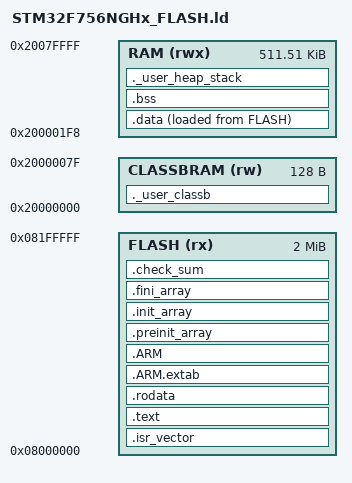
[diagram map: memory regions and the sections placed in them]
/*
*****************************************************************************
**

**  File        : STM32F756NGHx_FLASH.ld
**
**  Abstract    : Linker script for STM32F756NGHx Device with
**                1024KByte FLASH, 320KByte RAM
**
**                Set heap size, stack size and stack location according
**                to application requirements.
**
**                Set memory bank area and size if external memory is used.
**
**  Target      : STMicroelectronics STM32
**
**
**  Distribution: The file is distributed as is, without any warranty
**                of any kind.
**
*****************************************************************************
** @attention
**
** <h2><center>&copy; COPYRIGHT(c) 2014 Ac6</center></h2>
**
** Redistribution and use in source and binary forms, with or without modification,
** are permitted provided that the following conditions are met:
**   1. Redistributions of source code must retain the above copyright notice,
**      this list of conditions and the following disclaimer.
**   2. Redistributions in binary form must reproduce the above copyright notice,
**      this list of conditions and the following disclaimer in the documentation
**      and/or other materials provided with the distribution.
**   3. Neither the name of Ac6 nor the names of its contributors
**      may be used to endorse or promote products derived from this software
**      without specific prior written permission.
**
** THIS SOFTWARE IS PROVIDED BY THE COPYRIGHT HOLDERS AND CONTRIBUTORS "AS IS"
** AND ANY EXPRESS OR IMPLIED WARRANTIES, INCLUDING, BUT NOT LIMITED TO, THE
** IMPLIED WARRANTIES OF MERCHANTABILITY AND FITNESS FOR A PARTICULAR PURPOSE ARE
** DISCLAIMED. IN NO EVENT SHALL THE COPYRIGHT HOLDER OR CONTRIBUTORS BE LIABLE
** FOR ANY DIRECT, INDIRECT, INCIDENTAL, SPECIAL, EXEMPLARY, OR CONSEQUENTIAL
** DAMAGES (INCLUDING, BUT NOT LIMITED TO, PROCUREMENT OF SUBSTITUTE GOODS OR
** SERVICES; LOSS OF USE, DATA, OR PROFITS; OR BUSINESS INTERRUPTION) HOWEVER
** CAUSED AND ON ANY THEORY OF LIABILITY, WHETHER IN CONTRACT, STRICT LIABILITY,
** OR TORT (INCLUDING NEGLIGENCE OR OTHERWISE) ARISING IN ANY WAY OUT OF THE USE
** OF THIS SOFTWARE, EVEN IF ADVISED OF THE POSSIBILITY OF SUCH DAMAGE.
**
*****************************************************************************
*/

/* Entry Point */
ENTRY(Reset_Handler)

/* Highest address of the user mode stack */
_estack = 0x2004FFFF;    /* end of RAM */
/* Generate a link error if heap and stack don't fit into RAM */
_Min_Heap_Size = 0x200;      /* required amount of heap  */
_Min_Stack_Size = 0x400; /* required amount of stack */

/* Specify the memory areas */
MEMORY
{
FLASH (rx)      : ORIGIN = 0x08000000, LENGTH = 2048K
CLASSBRAM (rw)   : ORIGIN = 0x20000000, LENGTH = 0x80
/* RAM (xrw)        : ORIGIN = 0x20000080, LENGTH = 0x4FF80 */
 RAM (rwx)  : ORIGIN = 0x200001F8, LENGTH = 512K - 0x1F8
}

/* Define output sections */
SECTIONS
{
  /* The startup code goes first into FLASH */
  .isr_vector :
  {
    . = ALIGN(4);
    KEEP(*(.isr_vector)) /* Startup code */
    . = ALIGN(4);
  } >FLASH

  /* The program code and other data goes into FLASH */
  .text :
  {
    . = ALIGN(4);
    *(.text)           /* .text sections (code) */
    *(.text*)          /* .text* sections (code) */
    *(.glue_7)         /* glue arm to thumb code */
    *(.glue_7t)        /* glue thumb to arm code */
    *(.eh_frame)

    KEEP (*(.init))
    KEEP (*(.fini))

    . = ALIGN(4);
    _etext = .;        /* define a global symbols at end of code */
  } >FLASH

  /* Constant data goes into FLASH */
  .rodata :
  {
    . = ALIGN(4);
    *(.rodata)         /* .rodata sections (constants, strings, etc.) */
    *(.rodata*)        /* .rodata* sections (constants, strings, etc.) */
    . = ALIGN(4);
  } >FLASH

  .ARM.extab   : { *(.ARM.extab* .gnu.linkonce.armextab.*) } >FLASH
  .ARM : {
    __exidx_start = .;
    *(.ARM.exidx*)
    __exidx_end = .;
  } >FLASH

  .preinit_array     :
  {
    PROVIDE_HIDDEN (__preinit_array_start = .);
    KEEP (*(.preinit_array*))
    PROVIDE_HIDDEN (__preinit_array_end = .);
  } >FLASH
  
  .init_array :
  {
    PROVIDE_HIDDEN (__init_array_start = .);
    KEEP (*(SORT(.init_array.*)))
    KEEP (*(.init_array*))
    PROVIDE_HIDDEN (__init_array_end = .);
  } >FLASH
  
  .fini_array :
  {
    PROVIDE_HIDDEN (__fini_array_start = .);
    KEEP (*(SORT(.fini_array.*)))
    KEEP (*(.fini_array*))
    PROVIDE_HIDDEN (__fini_array_end = .);
  } >FLASH

  /* used by the startup to initialize data */
  _sidata = LOADADDR(.data);

  /* Initialized data sections goes into RAM, load LMA copy after code */
  .data : 
  {
    . = ALIGN(4);
    _sdata = .;        /* create a global symbol at data start */
    *(stm32fxx_STLstartup.o)
    *(.data)           /* .data sections */
    *(.data*)          /* .data* sections */

    . = ALIGN(4);
    _edata = .;        /* define a global symbol at data end */
  } >RAM AT> FLASH

  /* check sum specified by user at the end of program in flash */
  .check_sum :
  {
  	. = ALIGN(64); /* alignement must correspond to the size of tested block at FLASH run time test */
  	PROVIDE( _Check_Sum = . );
  	/* check sum defined by user - see user manual */
  	/* LONG(0xc60373f1); */
    	LONG(0x0067B29E);
  } >FLASH
  
  /* Uninitialized data section */
  . = ALIGN(4);
  .bss(NOLOAD) :
  {
    /* This is used by the startup in order to initialize the .bss secion */
    _sbss = .;         /* define a global symbol at bss start */
    __bss_start__ = _sbss;
    *(.bss)
    *(.bss*)
    *(COMMON)

    . = ALIGN(4);
    _ebss = .;         /* define a global symbol at bss end */
    __bss_end__ = _ebss;
  } >RAM

  /* User_heap_stack section, used to check that there is enough RAM left */
  /* Willy Add __end__ = .; because mbed need it */
  ._user_heap_stack(NOLOAD) :
  {
    . = ALIGN(8);
	__end__ = .;     
    PROVIDE ( end_ = . );
    PROVIDE ( _end = . );
    . = . + _Min_Heap_Size;
    *(.stack_bottom)
    *(.stack_bottom*)
    . = . + _Min_Stack_Size;
    . = ALIGN(8);
  } >RAM

  
  /* User class B RAM region */
  ._user_classb(NOLOAD) :
  {
    . = ALIGN(4);
    *(.run_time_ram_buf)
    *(.run_time_ram_buf*)
    *(.run_time_ram_pnt)
    *(.run_time_ram_pnt*)
    
    . = ALIGN(4);
    PROVIDE(_classb_start = . );
    
    *(.class_b_ram)
    *(.class_b_ram*)
    . = ALIGN(4);
    *(.class_b_ram_rev)
    *(.class_b_ram_rev*)
    
    . = ALIGN(4);
    PROVIDE(_classb_end = . );
  } >CLASSBRAM

  /* Remove information from the standard libraries */
  /DISCARD/ :
  {
    libc.a ( * )
    libm.a ( * )
    libgcc.a ( * )
  }

  .ARM.attributes 0 : { *(.ARM.attributes) }
}


